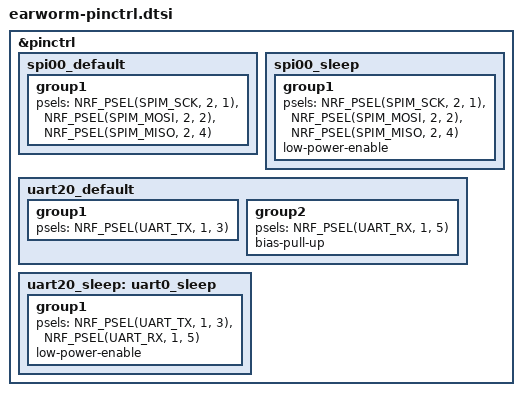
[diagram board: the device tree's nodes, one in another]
&pinctrl {
    // Accelerometer pin settings
    spi00_default: spi00_default {
		group1 {
			psels = <NRF_PSEL(SPIM_SCK, 2, 1)>,   // P2.01
				    <NRF_PSEL(SPIM_MOSI, 2, 2)>,  // P2.02
				    <NRF_PSEL(SPIM_MISO, 2, 4)>;  // P2.04
		};
	};

	spi00_sleep: spi00_sleep {
		group1 {
			psels = <NRF_PSEL(SPIM_SCK, 2, 1)>,   // P2.01
				    <NRF_PSEL(SPIM_MOSI, 2, 2)>,  // P2.02
				    <NRF_PSEL(SPIM_MISO, 2, 4)>;  // P2.04
			low-power-enable;
		};
	};

    // Serial Console / Test point settings
    uart20_default: uart20_default {
		group1 {
			psels = <NRF_PSEL(UART_TX, 1, 3)>;
		};
		group2 {
			psels = <NRF_PSEL(UART_RX, 1, 5)>;
			bias-pull-up;
		};
	};

	uart20_sleep: uart0_sleep {
		group1 {
			psels = <NRF_PSEL(UART_TX, 1, 3)>,
				    <NRF_PSEL(UART_RX, 1, 5)>;
			low-power-enable;
		};
    };
};
